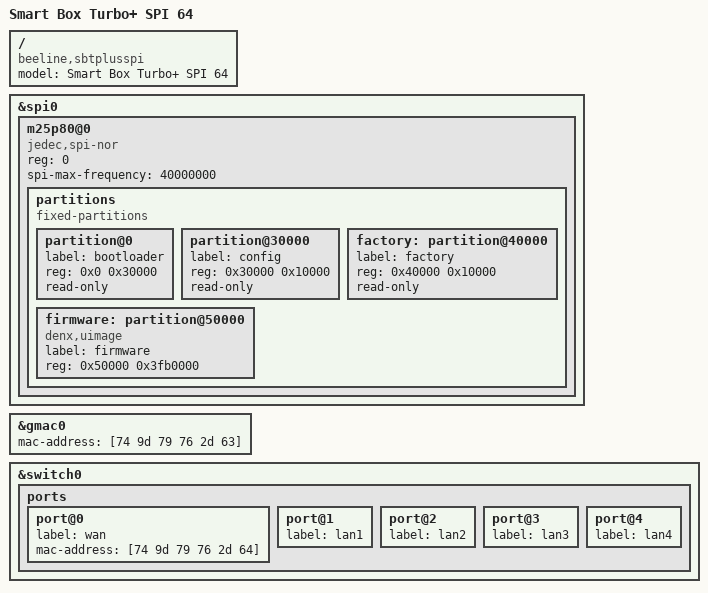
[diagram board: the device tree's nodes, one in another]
// SPDX-License-Identifier: GPL-2.0

#include "mt7621_beeline_sbtplus.dtsi"

/ {
	compatible = "beeline,sbtplusspi", "mediatek,mt7621-soc";
	model = "Smart Box Turbo+ SPI 64";
};

&spi0 {
	status = "okay";

	m25p80@0 {
		compatible = "jedec,spi-nor";
		reg = <0>;
		spi-max-frequency = <40000000>;

		partitions {
			compatible = "fixed-partitions";
			#address-cells = <1>;
			#size-cells = <1>;

			partition@0 {
				label = "bootloader";
				reg = <0x0 0x30000>;
				read-only;
			};

			partition@30000 {
				label = "config";
				reg = <0x30000 0x10000>;
				read-only;
			};

			factory: partition@40000 {
				label = "factory";
				reg = <0x40000 0x10000>;
				read-only;
			};

			firmware: partition@50000 {
				compatible = "denx,uimage";
				label = "firmware";
				reg = <0x50000 0x3fb0000>;
			};
		};
	};
};

&gmac0 {
	mac-address = [74 9d 79 76 2d 63];
};

&switch0 {
	ports {
		port@0 {
			status = "okay";
			label = "wan";
			mac-address = [74 9d 79 76 2d 64];
		};

		port@1 {
			status = "okay";
			label = "lan1";
		};

		port@2 {
			status = "okay";
			label = "lan2";
		};

		port@3 {
			status = "okay";
			label = "lan3";
		};

		port@4 {
			status = "okay";
			label = "lan4";
		};
	};
};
